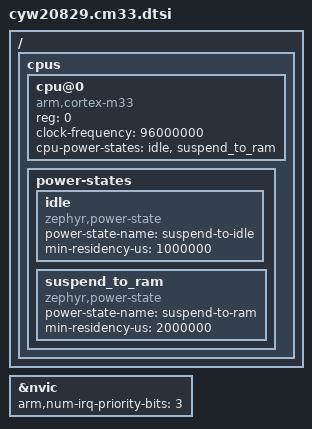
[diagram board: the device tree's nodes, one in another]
/*
 * Copyright (c) 2025 Infineon Technologies AG,
 * or an affiliate of Infineon Technologies AG.
 *
 * SPDX-License-Identifier: Apache-2.0
 */

#include <arm/armv8-m.dtsi>

/ {
	cpus {
		#address-cells = <1>;
		#size-cells = <0>;

		cpu@0 {
			device_type = "cpu";
			compatible = "arm,cortex-m33";
			reg = <0>;
			clock-frequency = <96000000>;
			cpu-power-states = <&idle &suspend_to_ram>;
		};

		power-states {
			idle: idle {
				compatible = "zephyr,power-state";
				power-state-name = "suspend-to-idle";
				min-residency-us = <1000000>;
			};

			suspend_to_ram: suspend_to_ram {
				compatible = "zephyr,power-state";
				power-state-name = "suspend-to-ram";
				min-residency-us = <2000000>;
			};
		};
	};
};

&nvic {
	arm,num-irq-priority-bits = <3>;
};
